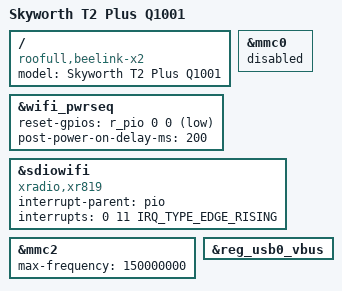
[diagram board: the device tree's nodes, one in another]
// SPDX-License-Identifier: (GPL-2.0+)
/*
 * Copyright (C) 2022 Zhao Yu <574249312@qq.com>
 */

#include "sun8i-h3-beelink-x2.dts"

/ {
	model = "Skyworth T2 Plus Q1001";
	compatible = "roofull,beelink-x2", "allwinner,sun8i-h3";

};

&wifi_pwrseq {
	reset-gpios = <&r_pio 0 0 GPIO_ACTIVE_LOW>; /* PL0 */
	post-power-on-delay-ms = <200>;
};

/* sdcard */
&mmc0 {
	status = "disabled";
};

&sdiowifi {
	compatible = "xradio,xr819";
	interrupt-parent = <&pio>;
	interrupts = <0 11 IRQ_TYPE_EDGE_RISING>; /* PA11 */
	interrupt-names = "host-wake";
}

/* eMMC */
&mmc2 {
	max-frequency = <150000000>;
	status = "okay";
};

&reg_usb0_vbus {
	//regulator-always-on;
	status = "okay";
};

